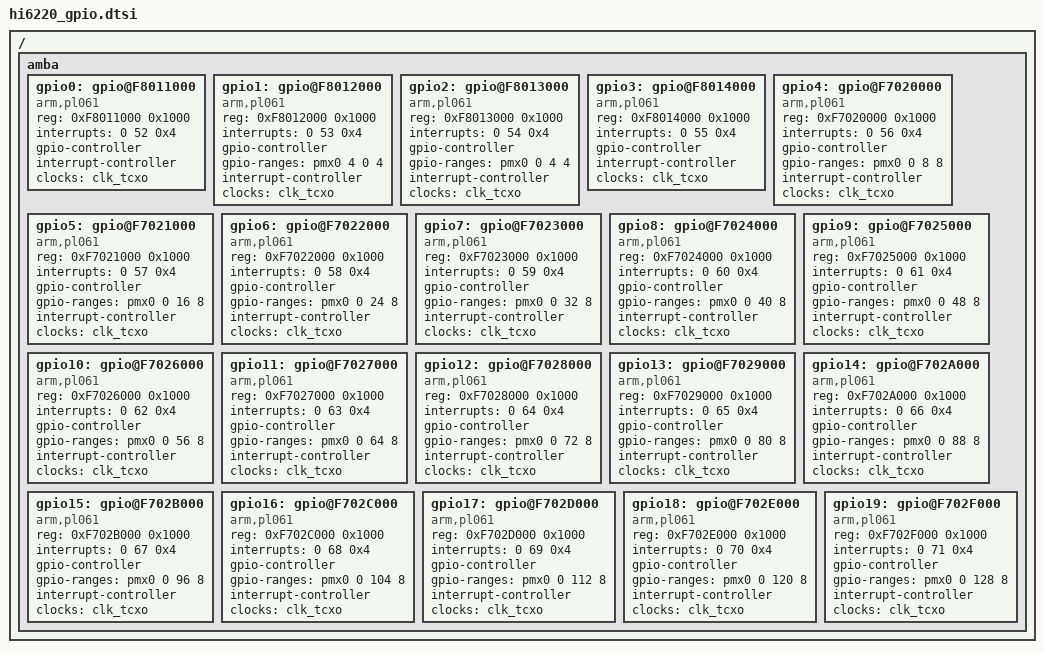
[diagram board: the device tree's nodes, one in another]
	/*
 * Hisilicon Ltd. Hi6620 SoC
 *
 * Copyright (C) 2012-2013 Hisilicon Ltd.
 * Author: t00202031 <tuchangmao@huawei.com>
 *
 * This program is free software; you can redistribute it and/or modify
 * it under the terms of the GNU General Public License version 2 as
 * publishhed by the Free Software Foundation.
 */

/{
	amba{
		gpio0: gpio@F8011000 {
			compatible = "arm,pl061", "arm,primecell";
			reg = <0xF8011000 0x1000>;
			interrupts = <0 52 0x4>;
			gpio-controller;
			#gpio-cells = <2>;
			interrupt-controller;
			#interrupt-cells = <2>;
			/*clocks = <&pclk_gpio0 &pclk>;*/
			/*clock-names = "pclk_gpio0", "apb_pclk";*/
			clocks = <&clk_tcxo>;
                        clock-names = "apb_pclk";
			/*gpio,hwspinlock;*/
			status = "ok";
		};

		gpio1: gpio@F8012000 {
			compatible = "arm,pl061", "arm,primecell";
			reg = <0xF8012000 0x1000>;
			interrupts = <0 53 0x4>;
			gpio-controller;
			#gpio-cells = <2>;
			gpio-ranges = <&pmx0 4 0 4>;
			interrupt-controller;
			#interrupt-cells = <2>;
			/*clocks = <&pclk_gpio1 &pclk>;*/
			/*clock-names = "pclk_gpio1", "apb_pclk";*/
			clocks = <&clk_tcxo>;
                        clock-names = "apb_pclk";
			status = "ok";
		};

		gpio2: gpio@F8013000 {
			compatible = "arm,pl061", "arm,primecell";
			reg = <0xF8013000 0x1000>;
			interrupts = <0 54 0x4>;
			gpio-controller;
			#gpio-cells = <2>;
			gpio-ranges = <&pmx0 0 4 4>;
			interrupt-controller;
			#interrupt-cells = <2>;
			/*clocks = <&pclk_gpio2 &pclk>;*/
			/*clock-names = "pclk_gpio2", "apb_pclk";*/
			clocks = <&clk_tcxo>;
                        clock-names = "apb_pclk";
			status = "ok";
		};

		gpio3: gpio@F8014000 {
			compatible = "arm,pl061", "arm,primecell";
			reg = <0xF8014000 0x1000>;
			interrupts = <0 55 0x4>;
			gpio-controller;
			#gpio-cells = <2>;
			interrupt-controller;
			#interrupt-cells = <2>;
			/*clocks = <&pclk_gpio3 &pclk>;*/
			/*clock-names = "pclk_gpio3", "apb_pclk";*/
			clocks = <&clk_tcxo>;
                        clock-names = "apb_pclk";
			status = "ok";
		};

		gpio4: gpio@F7020000 {
			compatible = "arm,pl061", "arm,primecell";
			reg = <0xF7020000 0x1000>;
			interrupts = <0 56 0x4>;
			gpio-controller;
			#gpio-cells = <2>;
			gpio-ranges = <&pmx0 0 8 8>;
			interrupt-controller;
			#interrupt-cells = <2>;
			/*clocks = <&pclk_gpio4 &pclk>;*/
			/*clock-names = "pclk_gpio4", "apb_pclk";*/
			clocks = <&clk_tcxo>;
                        clock-names = "apb_pclk";
			status = "ok";
		};

		gpio5: gpio@F7021000 {
			compatible = "arm,pl061", "arm,primecell";
			reg = <0xF7021000 0x1000>;
			interrupts = <0 57 0x4>;
			gpio-controller;
			#gpio-cells = <2>;
			gpio-ranges = <&pmx0 0 16 8>;
			interrupt-controller;
			#interrupt-cells = <2>;
			/*clocks = <&pclk_gpio5 &pclk>;*/
			/*clock-names = "pclk_gpio5", "apb_pclk";*/
			clocks = <&clk_tcxo>;
                        clock-names = "apb_pclk";
			status = "ok";
		};

		gpio6: gpio@F7022000 {
			compatible = "arm,pl061", "arm,primecell";
			reg = <0xF7022000 0x1000>;
			interrupts = <0 58 0x4>;
			gpio-controller;
			#gpio-cells = <2>;
			gpio-ranges = <&pmx0 0 24 8>;
			interrupt-controller;
			#interrupt-cells = <2>;
			/*clocks = <&pclk_gpio6 &pclk>;*/
			/*clock-names = "pclk_gpio6", "apb_pclk";*/
			clocks = <&clk_tcxo>;
                        clock-names = "apb_pclk";
			status = "ok";
		};

		gpio7: gpio@F7023000 {
			compatible = "arm,pl061", "arm,primecell";
			reg = <0xF7023000 0x1000>;
			interrupts = <0 59 0x4>;
			gpio-controller;
			#gpio-cells = <2>;
			gpio-ranges = <&pmx0 0 32 8>;
			interrupt-controller;
			#interrupt-cells = <2>;
			/*clocks = <&pclk_gpio7 &pclk>;*/
			/*clock-names = "pclk_gpio7", "apb_pclk";*/
			clocks = <&clk_tcxo>;
                        clock-names = "apb_pclk";
			status = "ok";
		};

		gpio8: gpio@F7024000 {
			compatible = "arm,pl061", "arm,primecell";
			reg = <0xF7024000 0x1000>;
			interrupts = <0 60 0x4>;
			gpio-controller;
			#gpio-cells = <2>;
			gpio-ranges = <&pmx0 0 40 8>;
			interrupt-controller;
			#interrupt-cells = <2>;
			/*clocks = <&pclk_gpio8 &pclk>;*/
			/*clock-names = "pclk_gpio8", "apb_pclk";*/
			clocks = <&clk_tcxo>;
                        clock-names = "apb_pclk";
			status = "ok";
		};

		gpio9: gpio@F7025000 {
			compatible = "arm,pl061", "arm,primecell";
			reg = <0xF7025000 0x1000>;
			interrupts = <0 61 0x4>;
			gpio-controller;
			#gpio-cells = <2>;
			gpio-ranges = <&pmx0 0 48 8>;
			interrupt-controller;
			#interrupt-cells = <2>;
			/*clocks = <&pclk_gpio9 &pclk>;*/
			/*clock-names = "pclk_gpio9", "apb_pclk";*/
			clocks = <&clk_tcxo>;
                        clock-names = "apb_pclk";
			status = "ok";
		};

		gpio10: gpio@F7026000 {
			compatible = "arm,pl061", "arm,primecell";
			reg = <0xF7026000 0x1000>;
			interrupts = <0 62 0x4>;
			gpio-controller;
			#gpio-cells = <2>;
			gpio-ranges = <&pmx0 0 56 8>;
			interrupt-controller;
			#interrupt-cells = <2>;
			/*clocks = <&pclk_gpio10 &pclk>;*/
			/*clock-names = "pclk_gpio10", "apb_pclk";*/
			clocks = <&clk_tcxo>;
                        clock-names = "apb_pclk";
			status = "ok";
		};

		gpio11: gpio@F7027000 {
			compatible = "arm,pl061", "arm,primecell";
			reg = <0xF7027000 0x1000>;
			interrupts = <0 63 0x4>;
			gpio-controller;
			#gpio-cells = <2>;
			gpio-ranges = <&pmx0 0 64 8>;
			interrupt-controller;
			#interrupt-cells = <2>;
			/*clocks = <&pclk_gpio11 &pclk>;*/
			/*clock-names = "pclk_gpio11", "apb_pclk";*/
			clocks = <&clk_tcxo>;
                        clock-names = "apb_pclk";
			status = "ok";
		};

		gpio12: gpio@F7028000 {
			compatible = "arm,pl061", "arm,primecell";
			reg = <0xF7028000 0x1000>;
			interrupts = <0 64 0x4>;
			gpio-controller;
			#gpio-cells = <2>;
			gpio-ranges = <&pmx0 0 72 8>;
			interrupt-controller;
			#interrupt-cells = <2>;
			/*clocks = <&pclk_gpio12 &pclk>;*/
			/*clock-names = "pclk_gpio12", "apb_pclk";*/
			clocks = <&clk_tcxo>;
                        clock-names = "apb_pclk";
			status = "ok";
		};

		gpio13: gpio@F7029000 {
			compatible = "arm,pl061", "arm,primecell";
			reg = <0xF7029000 0x1000>;
			interrupts = <0 65 0x4>;
			gpio-controller;
			#gpio-cells = <2>;
			gpio-ranges = <&pmx0 0 80 8>;
			interrupt-controller;
			#interrupt-cells = <2>;
			/*clocks = <&pclk_gpio13 &pclk>;*/
			/*clock-names = "pclk_gpio13", "apb_pclk";*/
			clocks = <&clk_tcxo>;
                        clock-names = "apb_pclk";
			status = "ok";
		};

		gpio14: gpio@F702A000 {
			compatible = "arm,pl061", "arm,primecell";
			reg = <0xF702A000 0x1000>;
			interrupts = <0 66 0x4>;
			gpio-controller;
			#gpio-cells = <2>;
			gpio-ranges = <&pmx0 0 88 8>;
			interrupt-controller;
			#interrupt-cells = <2>;
			/*clocks = <&pclk_gpio14 &pclk>;*/
			/*clock-names = "pclk_gpio14", "apb_pclk";*/
			clocks = <&clk_tcxo>;
                        clock-names = "apb_pclk";
			status = "ok";
		};

		gpio15: gpio@F702B000 {
			compatible = "arm,pl061", "arm,primecell";
			reg = <0xF702B000 0x1000>;
			interrupts = <0 67 0x4>;
			gpio-controller;
			#gpio-cells = <2>;
			gpio-ranges = <&pmx0 0 96 8>;
			interrupt-controller;
			#interrupt-cells = <2>;
			/*clocks = <&pclk_gpio15 &pclk>;*/
			/*clock-names = "pclk_gpio15", "apb_pclk";*/
			clocks = <&clk_tcxo>;
                        clock-names = "apb_pclk";
			status = "ok";
		};

		gpio16: gpio@F702C000 {
			compatible = "arm,pl061", "arm,primecell";
			reg = <0xF702C000 0x1000>;
			interrupts = <0 68 0x4>;
			gpio-controller;
			#gpio-cells = <2>;
			gpio-ranges = <&pmx0 0 104 8>;
			interrupt-controller;
			#interrupt-cells = <2>;
			/*clocks = <&pclk_gpio16 &pclk>;*/
			/*clock-names = "pclk_gpio16", "apb_pclk";*/
			clocks = <&clk_tcxo>;
                        clock-names = "apb_pclk";
			status = "ok";
		};

		gpio17: gpio@F702D000 {
			compatible = "arm,pl061", "arm,primecell";
			reg = <0xF702D000 0x1000>;
			interrupts = <0 69 0x4>;
			gpio-controller;
			#gpio-cells = <2>;
			gpio-ranges = <&pmx0 0 112 8>;
			interrupt-controller;
			#interrupt-cells = <2>;
			/*clocks = <&pclk_gpio17 &pclk>;*/
			/*clock-names = "pclk_gpio17", "apb_pclk";*/
			clocks = <&clk_tcxo>;
                        clock-names = "apb_pclk";
			status = "ok";
		};

		gpio18: gpio@F702E000 {
			compatible = "arm,pl061", "arm,primecell";
			reg = <0xF702E000 0x1000>;
			interrupts = <0 70 0x4>;
			gpio-controller;
			#gpio-cells = <2>;
			gpio-ranges = <&pmx0 0 120 8>;
			interrupt-controller;
			#interrupt-cells = <2>;
			/*clocks = <&pclk_gpio18 &pclk>;*/
			/*clock-names = "pclk_gpio18", "apb_pclk";*/
			clocks = <&clk_tcxo>;
                        clock-names = "apb_pclk";
			status = "ok";
		};

		gpio19: gpio@F702F000 {
			compatible = "arm,pl061", "arm,primecell";
			reg = <0xF702F000 0x1000>;
			interrupts = <0 71 0x4>;
			gpio-controller;
			#gpio-cells = <2>;
			gpio-ranges = <&pmx0 0 128 8>;
			interrupt-controller;
			#interrupt-cells = <2>;
			/*clocks = <&pclk_gpio19 &pclk>;*/
			/*clock-names = "pclk_gpio19", "apb_pclk";*/
			clocks = <&clk_tcxo>;
                        clock-names = "apb_pclk";
			status = "ok";
		};
	};
};
